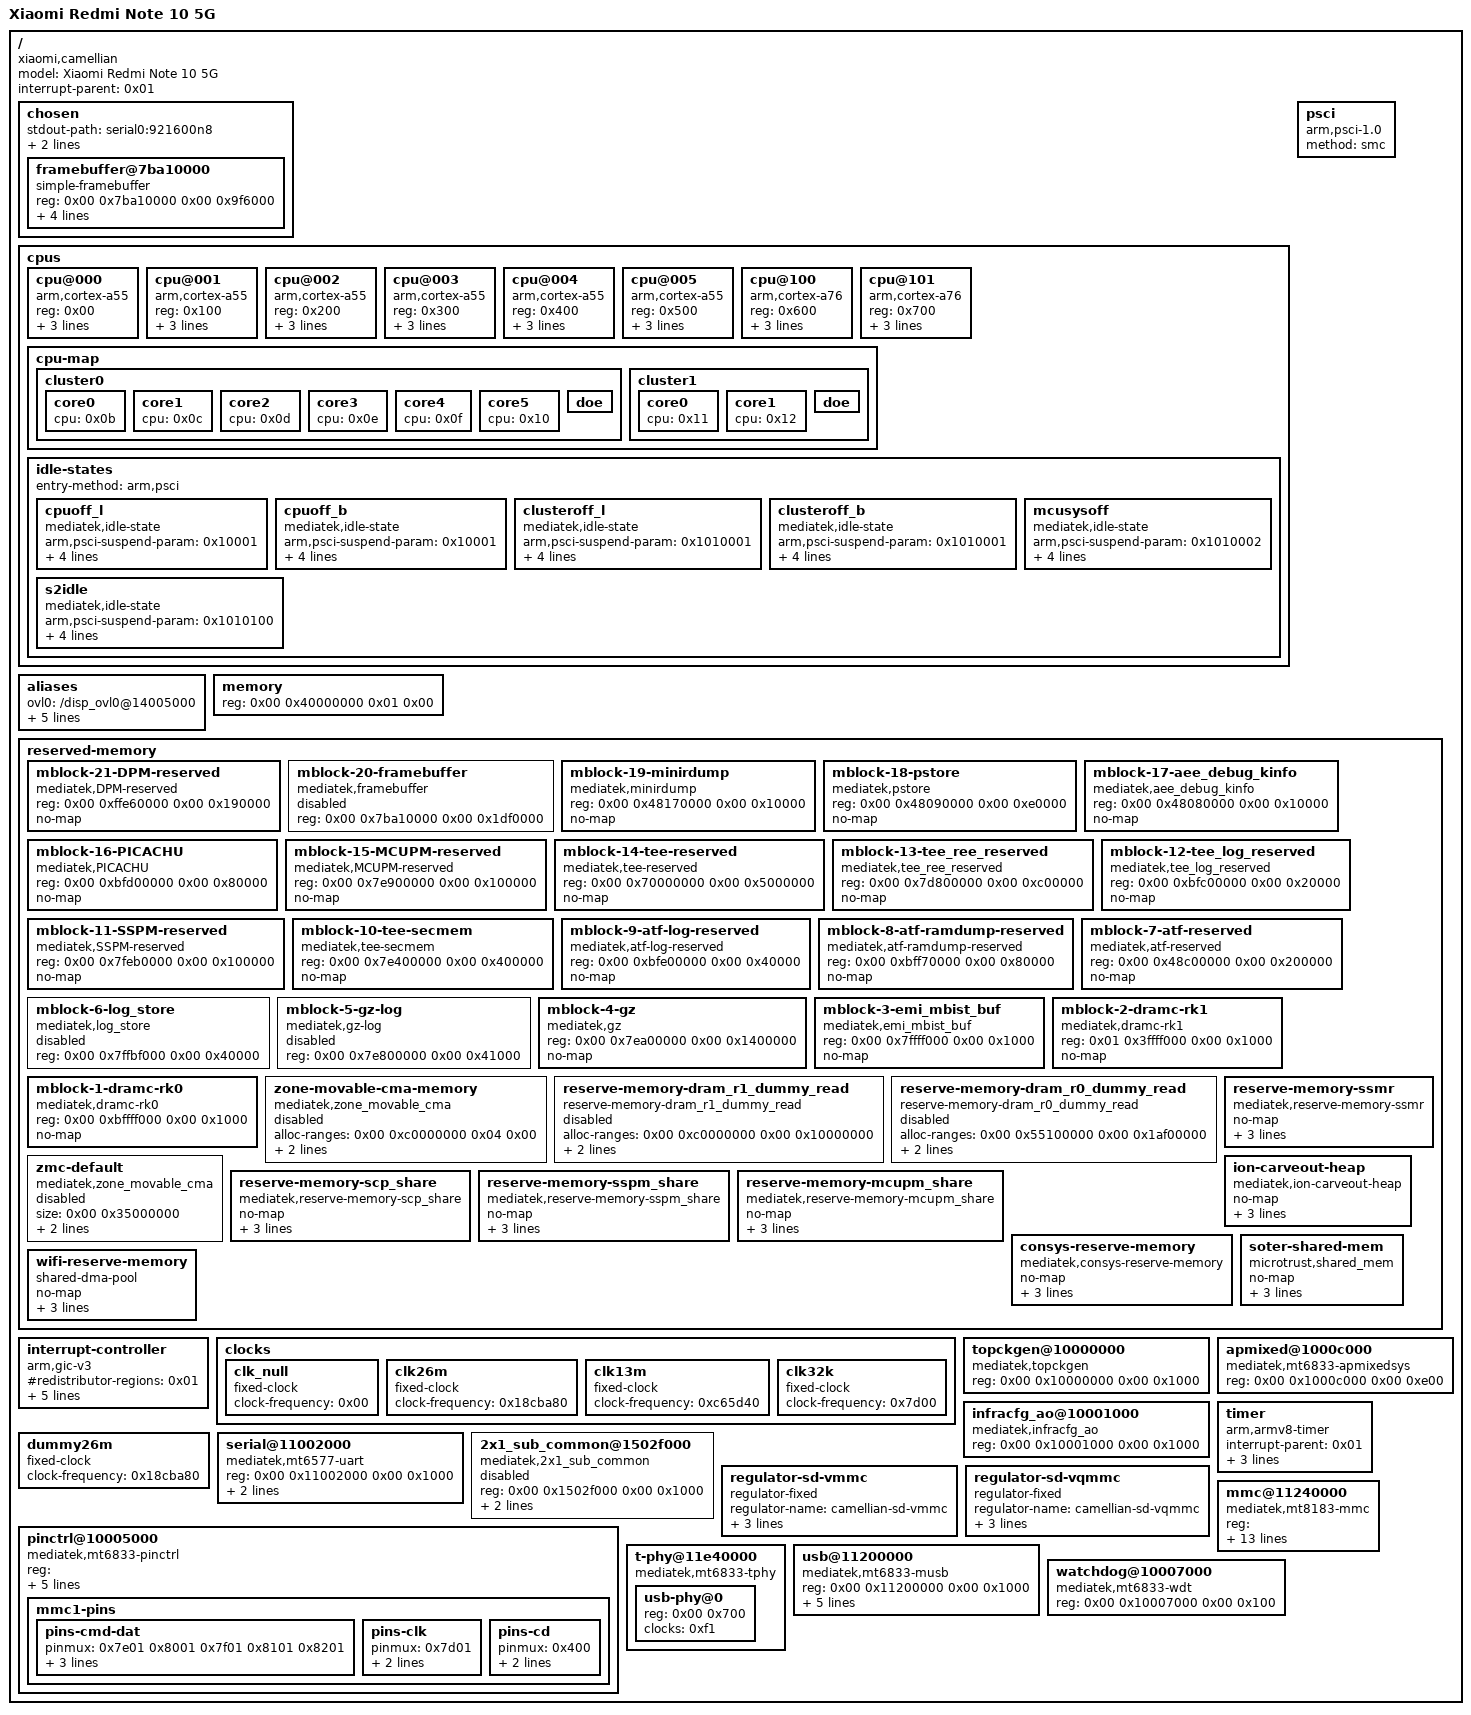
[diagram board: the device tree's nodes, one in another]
/dts-v1/;

/ {
	model = "Xiaomi Redmi Note 10 5G";
	compatible = "xiaomi,camellian\0mediatek,mt6833";
	interrupt-parent = <0x01>;
	#address-cells = <0x02>;
	#size-cells = <0x02>;








	chosen {
		#address-cells = <0x02>;
		#size-cells = <0x02>;
		ranges;
		stdout-path = "serial0:921600n8";
		bootargs = "console=ttyS0,921600n8 console=tty0 rdinit=/init clk_ignore_unused pd_ignore_unused panic=10 printk.devkmsg=on";

		framebuffer@7ba10000 {
			compatible = "simple-framebuffer";
			reg = <0x00 0x7ba10000 0x00 0x9f6000>;
			width = <0x438>;
			height = <0x960>;
			stride = <0x1100>;
			format = "a8r8g8b8";
			status = "okay";
		};
	};

	cpus {
		#address-cells = <0x01>;
		#size-cells = <0x00>;

		cpu@000 {
			device_type = "cpu";
			compatible = "arm,cortex-a55";
			reg = <0x00>;
			enable-method = "psci";
			clock-frequency = <0x77359400>;
			cpu-idle-states = <0x05 0x06 0x07 0x08>;
			phandle = <0x0b>;
		};

		cpu@001 {
			device_type = "cpu";
			compatible = "arm,cortex-a55";
			reg = <0x100>;
			enable-method = "psci";
			clock-frequency = <0x77359400>;
			cpu-idle-states = <0x05 0x06 0x07 0x08>;
			phandle = <0x0c>;
		};

		cpu@002 {
			device_type = "cpu";
			compatible = "arm,cortex-a55";
			reg = <0x200>;
			enable-method = "psci";
			clock-frequency = <0x77359400>;
			cpu-idle-states = <0x05 0x06 0x07 0x08>;
			phandle = <0x0d>;
		};

		cpu@003 {
			device_type = "cpu";
			compatible = "arm,cortex-a55";
			reg = <0x300>;
			enable-method = "psci";
			clock-frequency = <0x77359400>;
			cpu-idle-states = <0x05 0x06 0x07 0x08>;
			phandle = <0x0e>;
		};

		cpu@004 {
			device_type = "cpu";
			compatible = "arm,cortex-a55";
			reg = <0x400>;
			enable-method = "psci";
			clock-frequency = <0x77359400>;
			cpu-idle-states = <0x05 0x06 0x07 0x08>;
			phandle = <0x0f>;
		};

		cpu@005 {
			device_type = "cpu";
			compatible = "arm,cortex-a55";
			reg = <0x500>;
			enable-method = "psci";
			clock-frequency = <0x77359400>;
			cpu-idle-states = <0x05 0x06 0x07 0x08>;
			phandle = <0x10>;
		};

		cpu@100 {
			device_type = "cpu";
			compatible = "arm,cortex-a76";
			reg = <0x600>;
			enable-method = "psci";
			clock-frequency = <0x77359400>;
			cpu-idle-states = <0x09 0x0a 0x07 0x08>;
			phandle = <0x11>;
		};

		cpu@101 {
			device_type = "cpu";
			compatible = "arm,cortex-a76";
			reg = <0x700>;
			enable-method = "psci";
			clock-frequency = <0x77359400>;
			cpu-idle-states = <0x09 0x0a 0x07 0x08>;
			phandle = <0x12>;
		};

		cpu-map {

			cluster0 {

				core0 {
					cpu = <0x0b>;
				};

				core1 {
					cpu = <0x0c>;
				};

				core2 {
					cpu = <0x0d>;
				};

				core3 {
					cpu = <0x0e>;
				};

				core4 {
					cpu = <0x0f>;
				};

				core5 {
					cpu = <0x10>;
				};

				doe {
					phandle = <0xa7>;
				};
			};

			cluster1 {

				core0 {
					cpu = <0x11>;
				};

				core1 {
					cpu = <0x12>;
				};

				doe {
					phandle = <0xa8>;
				};
			};
		};

		idle-states {
			entry-method = "arm,psci";

			cpuoff_l {
				compatible = "mediatek,idle-state";
				arm,psci-suspend-param = <0x10001>;
				local-timer-stop;
				entry-latency-us = <0x32>;
				exit-latency-us = <0x64>;
				min-residency-us = <0x640>;
				phandle = <0x05>;
			};

			cpuoff_b {
				compatible = "mediatek,idle-state";
				arm,psci-suspend-param = <0x10001>;
				local-timer-stop;
				entry-latency-us = <0x32>;
				exit-latency-us = <0x64>;
				min-residency-us = <0x578>;
				phandle = <0x09>;
			};

			clusteroff_l {
				compatible = "mediatek,idle-state";
				arm,psci-suspend-param = <0x1010001>;
				local-timer-stop;
				entry-latency-us = <0x64>;
				exit-latency-us = <0xfa>;
				min-residency-us = <0x834>;
				phandle = <0x06>;
			};

			clusteroff_b {
				compatible = "mediatek,idle-state";
				arm,psci-suspend-param = <0x1010001>;
				local-timer-stop;
				entry-latency-us = <0x64>;
				exit-latency-us = <0xfa>;
				min-residency-us = <0x76c>;
				phandle = <0x0a>;
			};

			mcusysoff {
				compatible = "mediatek,idle-state";
				arm,psci-suspend-param = <0x1010002>;
				local-timer-stop;
				entry-latency-us = <0x12c>;
				exit-latency-us = <0x4b0>;
				min-residency-us = <0xa28>;
				phandle = <0x07>;
			};

			s2idle {
				compatible = "mediatek,idle-state";
				arm,psci-suspend-param = <0x1010100>;
				local-timer-stop;
				entry-latency-us = <0x1f4>;
				exit-latency-us = <0x578>;
				min-residency-us = <0xffffffff>;
				phandle = <0x08>;
			};
		};
	};


	psci {
		compatible = "arm,psci-1.0";
		method = "smc";
	};

	aliases {
		ovl0 = "/disp_ovl0@14005000";
		ovl3 = "/disp_ovl0_2l@14006000";
		rdma0 = "/disp_rdma0@14007000";
		dsi0 = "/dsi@14013000";
		ccorr0 = "/disp_ccorr0@1400b000";
		serial0 = "/serial@11002000";
	};






	memory {
		device_type = "memory";
		reg = <0x00 0x40000000 0x01 0x00>;
	};

	reserved-memory {
		#address-cells = <0x02>;
		#size-cells = <0x02>;
		ranges;
		phandle = <0xac>;

		mblock-21-DPM-reserved {
			reg = <0x00 0xffe60000 0x00 0x190000>;
			no-map;
			compatible = "mediatek,DPM-reserved";
		};

		mblock-20-framebuffer {
			status = "disabled";
			reg = <0x00 0x7ba10000 0x00 0x1df0000>;
			compatible = "mediatek,framebuffer";
		};

		mblock-19-minirdump {
			reg = <0x00 0x48170000 0x00 0x10000>;
			no-map;
			compatible = "mediatek,minirdump";
		};

		mblock-18-pstore {
			reg = <0x00 0x48090000 0x00 0xe0000>;
			no-map;
			compatible = "mediatek,pstore";
		};

		mblock-17-aee_debug_kinfo {
			phandle = <0xbb010000>;
			reg = <0x00 0x48080000 0x00 0x10000>;
			no-map;
			compatible = "mediatek,aee_debug_kinfo";
		};

		mblock-16-PICACHU {
			reg = <0x00 0xbfd00000 0x00 0x80000>;
			no-map;
			compatible = "mediatek,PICACHU";
		};

		mblock-15-MCUPM-reserved {
			reg = <0x00 0x7e900000 0x00 0x100000>;
			no-map;
			compatible = "mediatek,MCUPM-reserved";
		};

		mblock-14-tee-reserved {
			reg = <0x00 0x70000000 0x00 0x5000000>;
			no-map;
			compatible = "mediatek,tee-reserved";
		};

		mblock-13-tee_ree_reserved {
			reg = <0x00 0x7d800000 0x00 0xc00000>;
			no-map;
			compatible = "mediatek,tee_ree_reserved";
		};

		mblock-12-tee_log_reserved {
			reg = <0x00 0xbfc00000 0x00 0x20000>;
			no-map;
			compatible = "mediatek,tee_log_reserved";
		};

		mblock-11-SSPM-reserved {
			reg = <0x00 0x7feb0000 0x00 0x100000>;
			no-map;
			compatible = "mediatek,SSPM-reserved";
		};

		mblock-10-tee-secmem {
			reg = <0x00 0x7e400000 0x00 0x400000>;
			no-map;
			compatible = "mediatek,tee-secmem";
		};

		mblock-9-atf-log-reserved {
			reg = <0x00 0xbfe00000 0x00 0x40000>;
			no-map;
			compatible = "mediatek,atf-log-reserved";
		};

		mblock-8-atf-ramdump-reserved {
			reg = <0x00 0xbff70000 0x00 0x80000>;
			no-map;
			compatible = "mediatek,atf-ramdump-reserved";
		};

		mblock-7-atf-reserved {
			reg = <0x00 0x48c00000 0x00 0x200000>;
			no-map;
			compatible = "mediatek,atf-reserved";
		};

		mblock-6-log_store {
			status = "disabled";
			reg = <0x00 0x7ffbf000 0x00 0x40000>;
			compatible = "mediatek,log_store";
		};

		mblock-5-gz-log {
			status = "disabled";
			reg = <0x00 0x7e800000 0x00 0x41000>;
			compatible = "mediatek,gz-log";
		};

		mblock-4-gz {
			reg = <0x00 0x7ea00000 0x00 0x1400000>;
			no-map;
			compatible = "mediatek,gz";
		};

		mblock-3-emi_mbist_buf {
			reg = <0x00 0x7ffff000 0x00 0x1000>;
			no-map;
			compatible = "mediatek,emi_mbist_buf";
		};

		mblock-2-dramc-rk1 {
			reg = <0x01 0x3ffff000 0x00 0x1000>;
			no-map;
			compatible = "mediatek,dramc-rk1";
		};

		mblock-1-dramc-rk0 {
			reg = <0x00 0xbffff000 0x00 0x1000>;
			no-map;
			compatible = "mediatek,dramc-rk0";
		};

		zone-movable-cma-memory {
			status = "disabled";
			alloc-ranges = <0x00 0xc0000000 0x04 0x00>;
			alignment = <0x00 0x1000000>;
			size = <0x00 0x35000000>;
			compatible = "mediatek,zone_movable_cma";
		};

		reserve-memory-dram_r1_dummy_read {
			status = "disabled";
			alloc-ranges = <0x00 0xc0000000 0x00 0x10000000>;
			alignment = <0x00 0x1000>;
			size = <0x00 0x1000>;
			compatible = "reserve-memory-dram_r1_dummy_read";
		};

		reserve-memory-dram_r0_dummy_read {
			status = "disabled";
			alloc-ranges = <0x00 0x55100000 0x00 0x1af00000>;
			alignment = <0x00 0x1000>;
			size = <0x00 0x1000>;
			compatible = "reserve-memory-dram_r0_dummy_read";
		};

		reserve-memory-ssmr {
			compatible = "mediatek,reserve-memory-ssmr";
			no-map;
			size = <0x00 0x1000>;
			alignment = <0x00 0x1000>;
			alloc-ranges = <0x00 0xc0000000 0x04 0x00>;
		};

		zmc-default {
			status = "disabled";
			compatible = "mediatek,zone_movable_cma";
			size = <0x00 0x35000000>;
			alignment = <0x00 0x1000000>;
			alloc-ranges = <0x00 0xc0000000 0x04 0x00>;
		};

		reserve-memory-scp_share {
			compatible = "mediatek,reserve-memory-scp_share";
			no-map;
			size = <0x00 0x320000>;
			alignment = <0x00 0x1000000>;
			alloc-ranges = <0x00 0x50000000 0x00 0x40000000>;
		};

		reserve-memory-sspm_share {
			compatible = "mediatek,reserve-memory-sspm_share";
			no-map;
			status = <0x6f6b6179>;
			size = <0x00 0x510000>;
			alignment = <0x00 0x10000>;
			alloc-ranges = <0x00 0x40000000 0x00 0x60000000>;
		};

		reserve-memory-mcupm_share {
			compatible = "mediatek,reserve-memory-mcupm_share";
			no-map;
			status = "okay";
			size = <0x00 0x610000>;
			alignment = <0x00 0x10000>;
			alloc-ranges = <0x00 0x40000000 0x00 0x60000000>;
		};

		ion-carveout-heap {
			compatible = "mediatek,ion-carveout-heap";
			no-map;
			size = <0x00 0xc000>;
			alignment = <0x00 0x1000>;
			alloc-ranges = <0x00 0x40000000 0x00 0x80000000>;
		};

		consys-reserve-memory {
			compatible = "mediatek,consys-reserve-memory";
			no-map;
			size = <0x00 0x500000>;
			alignment = <0x00 0x1000000>;
			alloc-ranges = <0x00 0x40000000 0x00 0x80000000>;
		};

		soter-shared-mem {
			compatible = "microtrust,shared_mem";
			no-map;
			size = <0x00 0x800000>;
			alignment = <0x00 0x1000000>;
			alloc-ranges = <0x00 0x40000000 0x00 0x50000000>;
		};

		wifi-reserve-memory {
			compatible = "shared-dma-pool";
			no-map;
			size = <0x00 0x600000>;
			alignment = <0x00 0x1000000>;
			alloc-ranges = <0x00 0x40000000 0x00 0x80000000>;
			phandle = <0x49>;
		};
	};




	interrupt-controller {
		compatible = "arm,gic-v3";
		#interrupt-cells = <0x03>;
		#address-cells = <0x02>;
		#size-cells = <0x02>;
		#redistributor-regions = <0x01>;
		interrupt-parent = <0x01>;
		interrupt-controller;
		reg = <0x00 0xc000000 0x00 0x40000 0x00 0xc040000 0x00 0x200000>;
		interrupts = <0x01 0x09 0x04>;
		phandle = <0x01>;
	};



	clocks {

		clk_null {
			compatible = "fixed-clock";
			#clock-cells = <0x00>;
			clock-frequency = <0x00>;
			phandle = <0xaf>;
		};

		clk26m {
			compatible = "fixed-clock";
			#clock-cells = <0x00>;
			clock-frequency = <0x18cba80>;
			phandle = <0x2d>;
		};

		clk13m {
			compatible = "fixed-clock";
			#clock-cells = <0x00>;
			clock-frequency = <0xc65d40>;
			phandle = <0x3d>;
		};

		clk32k {
			compatible = "fixed-clock";
			#clock-cells = <0x00>;
			clock-frequency = <0x7d00>;
			phandle = <0xb0>;
		};
	};


	topckgen@10000000 {
		status = "okay";
		compatible = "mediatek,topckgen\0mediatek,mt6833-topckgen\0syscon";
		reg = <0x00 0x10000000 0x00 0x1000>;
		#clock-cells = <0x01>;
		phandle = <0x30>;
	};



	infracfg_ao@10001000 {
		status = "okay";
		compatible = "mediatek,infracfg_ao\0mediatek,mt6833-infracfg_ao\0syscon";
		reg = <0x00 0x10001000 0x00 0x1000>;
		#clock-cells = <0x01>;
		phandle = <0x2f>;
	};

































	apmixed@1000c000 {
		status = "okay";
		compatible = "mediatek,mt6833-apmixedsys\0syscon";
		reg = <0x00 0x1000c000 0x00 0xe00>;
		#clock-cells = <0x01>;
		phandle = <0x4a>;
	};



























	timer {
		compatible = "arm,armv8-timer";
		interrupt-parent = <0x01>;
		interrupts = <0x01 0x0d 0x04 0x01 0x0e 0x04 0x01 0x0b 0x04 0x01 0x0a 0x04>;
		clock-frequency = <0xc65d40>;
		phandle = <0xf0>;
	};

	dummy26m {
		compatible = "fixed-clock";
		clock-frequency = <0x18cba80>;
		phandle = <0xf1>;
		#clock-cells = <0x00>;
	};


	serial@11002000 {
		compatible = "mediatek,mt6577-uart";
		reg = <0x00 0x11002000 0x00 0x1000>;
		interrupts = <0x00 0x6d 0x04>;
		phandle = <0xf2>;
		clocks = <0xf1 0xf1>;
		clock-names = "baud\0bus";
		status = "okay";
	};
























































































































































































































































































	2x1_sub_common@1502f000 {
		status = "disabled";
		compatible = "mediatek,2x1_sub_common\0mediatek,smi_common";
		reg = <0x00 0x1502f000 0x00 0x1000>;
		clocks = <0x32 0x06>;
		clock-names = "scp-isp";
		mediatek,smi-id = <0x1c>;
	};







































































































































	regulator-sd-vmmc {
		compatible = "regulator-fixed";
		regulator-name = "camellian-sd-vmmc";
		regulator-min-microvolt = <0x325aa0>;
		regulator-max-microvolt = <0x325aa0>;
		regulator-always-on;
		phandle = <0x1bc>;
	};

	regulator-sd-vqmmc {
		compatible = "regulator-fixed";
		regulator-name = "camellian-sd-vqmmc";
		regulator-min-microvolt = <0x325aa0>;
		regulator-max-microvolt = <0x325aa0>;
		regulator-always-on;
		phandle = <0x1bd>;
	};

	pinctrl@10005000 {
		compatible = "mediatek,mt6833-pinctrl";
		reg = <0x00 0x10005000 0x00 0x1000 0x00 0x11c30000 0x00 0x1000 0x00 0x11d10000 0x00 0x1000 0x00 0x11d40000 0x00 0x1000 0x00 0x11e20000 0x00 0x1000 0x00 0x11e60000 0x00 0x1000 0x00 0x11ea0000 0x00 0x1000 0x00 0x1000b000 0x00 0x1000>;
		reg-names = "gpio\0iocfg_rb\0iocfg_bm\0iocfg_br\0iocfg_lm\0iocfg_bl\0iocfg_rt\0eint";
		gpio-controller;
		#gpio-cells = <0x02>;
		gpio-ranges = <0xa6 0x00 0x00 0xc9>;
		interrupt-controller;
		#interrupt-cells = <0x02>;
		interrupts = <0x00 0xd4 0x04>;
		phandle = <0xa6>;

		mmc1-pins {
			phandle = <0x1bb>;

			pins-cmd-dat {
				pinmux = <0x7e01 0x8001 0x7f01 0x8101 0x8201>;
				input-enable;
				drive-strength = <0x08>;
				bias-pull-up = <0x65>;
			};

			pins-clk {
				pinmux = <0x7d01>;
				drive-strength = <0x08>;
				bias-pull-down = <0x66>;
			};

			pins-cd {
				pinmux = <0x400>;
				input-enable;
				bias-pull-up;
			};
		};
	};

	mmc@11240000 {
		compatible = "mediatek,mt8183-mmc";
		reg = <0x00 0x11240000 0x00 0x1000 0x00 0x11c70000 0x00 0x1000>;
		interrupts = <0x00 0x67 0x04>;
		clocks = <0x30 0xb6 0x2f 0x1d 0x2f 0x27>;
		clock-names = "source\0hclk\0source_cg";
		pinctrl-names = "default";
		pinctrl-0 = <0x1bb>;
		bus-width = <0x04>;
		max-frequency = <0x17d7840>;
		cap-sd-highspeed;
		no-1-8-v;
		cd-gpios = <0xa6 0x04 0x00>;
		vmmc-supply = <0x1bc>;
		vqmmc-supply = <0x1bd>;
		no-sdio;
		no-mmc;
		phandle = <0x1bf>;
	};

	t-phy@11e40000 {
		compatible = "mediatek,mt6833-tphy\0mediatek,generic-tphy-v2";
		#address-cells = <0x01>;
		#size-cells = <0x01>;
		ranges = <0x00 0x00 0x11e40000 0x1000>;
		phandle = <0x1c0>;

		usb-phy@0 {
			reg = <0x00 0x700>;
			clocks = <0xf1>;
			clock-names = "ref";
			#phy-cells = <0x01>;
			phandle = <0x1be>;
		};
	};

	usb@11200000 {
		compatible = "mediatek,mt6833-musb\0mediatek,mtk-musb";
		reg = <0x00 0x11200000 0x00 0x1000>;
		interrupts = <0x00 0x60 0x04>;
		interrupt-names = "mc";
		phys = <0x1be 0x03>;
		dr_mode = "peripheral";
		maximum-speed = "high-speed";
		clocks = <0x2f 0x34 0x30 0xbe 0x30 0x23>;
		clock-names = "main\0mcu\0univpll";
		phandle = <0x1c1>;
	};

	watchdog@10007000 {
		compatible = "mediatek,mt6833-wdt\0mediatek,mt6589-wdt";
		reg = <0x00 0x10007000 0x00 0x100>;
		#reset-cells = <0x01>;
	};

	__symbols__ {
		sd_vmmc = "/regulator-sd-vmmc";
		sd_vqmmc = "/regulator-sd-vqmmc";
		pio_ml = "/pinctrl@10005000";
		mmc1_pins = "/pinctrl@10005000/mmc1-pins";
		mmc1 = "/mmc@11240000";
		u2phy = "/t-phy@11e40000";
		u2port0 = "/t-phy@11e40000/usb-phy@0";
		usb_otg = "/usb@11200000";
	};
};
